# AT32F403A register map
Vendor: Keil; Series: AT32F403A; File version: 1.0
CPU: CM4 r0p1, little endian, no MPU, FPU, 4 interrupt priority bits
Registers are 32-bit, read-write, reset 0x0 unless marked. A register's access mark holds for its fields unless they carry their own. Offsets are from the block's base; [hi:lo] are bit positions; {n}, {i} and the like mark numbered series; 'fields as' and 'values as' point back to an identical list.

## CRM — Clock and reset management
Base 0x40021000
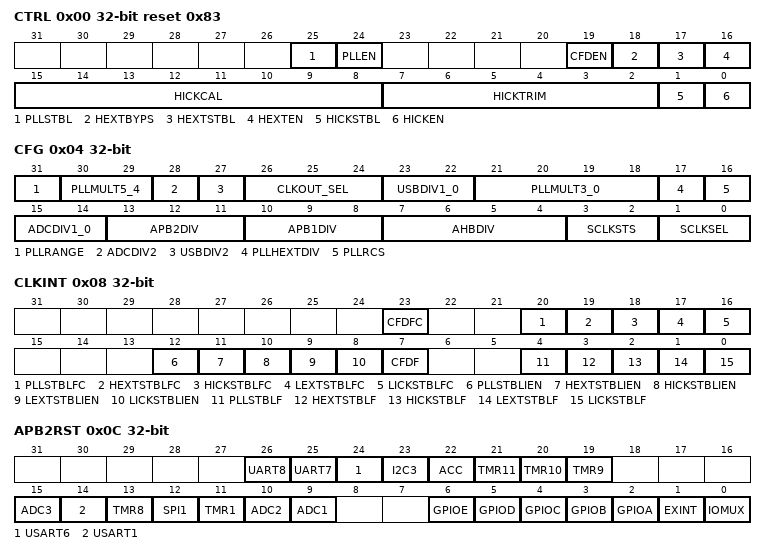
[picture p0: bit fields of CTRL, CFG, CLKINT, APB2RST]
0x00 CTRL reset 0x83 — Clock control register
  [25] PLLSTBL ro — PLL clock ready flag
    0=NotReady; 1=Ready
  [24] PLLEN — PLL enable
    on read: 0=Disabled (PLL is disabled); 1=Enabled (PLL is enabled) | on write: 0=Disable (PLL disable); 1=Enable (PLL enable)
  [19] CFDEN — Clock failure detection enable
    on read: 0=Disabled (Clock failure detector is disabled); 1=Enabled (Clock failure detector is enabled) | on write: 0=Disable (Clock failure detector disable); 1=Enable (Clock failure detector enable)
  [18] HEXTBYPS — High speed exernal crystal bypass
    on read: 0=Disabled (High speed external crystal bypass is disabled); 1=Enabled (High speed external crystal bypass is enabled) | on write: 0=Disable (High speed external crystal bypass disable); 1=Enable (High speed external crystal bypass enable)
  [17] HEXTSTBL ro — High speed exernal crystal ready flag
    0=NotReady; 1=Ready
  [16] HEXTEN — High speed exernal crystal enable
    on read: 0=Disabled (High speed external crystal is disabled); 1=Enabled (High speed external crystal is enabled) | on write: 0=Disable (High speed external crystal disable); 1=Enable (High speed external crystal enable)
  [15:8] HICKCAL ro — High speed internal clock calibration
  [7:2] HICKTRIM — High speed internal clock trimming
  [1] HICKSTBL ro — High speed internal clock ready flag
    0=NotReady; 1=Ready
  [0] HICKEN — High speed internal clock enable
    on read: 0=Disabled (High speed internal clock is disabled); 1=Enabled (High speed internal clock is enabled) | on write: 0=Disable (High speed internal clock disable); 1=Enable (High speed internal clock enable)
0x04 CFG — Clock configuration register (CRM_CFG)
  [31] PLLRANGE — PLL clock output frequency up 72MHz or not
  [30:29] PLLMULT5_4 — PLL Multiplication Factor bit5 and bit4
  [28] ADCDIV2 — ADC division bit2
  [27] USBDIV2 — USB division bit2
  [26:24] CLKOUT_SEL — Clock output selection bit2 to bit0
  [23:22] USBDIV1_0 — USB division bit1 and bit0
  [21:18] PLLMULT3_0 — PLL Multiplication Factor bit3 to bit0
  [17] PLLHEXTDIV — HEXT division selection for PLL entry clock
    0=HEXT; 1=Div2 (HEXT/2)
  [16] PLLRCS — PLL reference clock select
  [15:14] ADCDIV1_0 — ADC division bit1 and bit0
  [13:11] APB2DIV — APB2 division
    4=Div2 (HCLK divided by 2); 5=Div4 (HCLK divided by 4); 6=Div8 (HCLK divided by 8); 7=Div16 (HCLK divided by 16); other=HCLK (The divided HCLK is used as APB clock)
  [10:8] APB1DIV — APB1 division
    values as APB2DIV
  [7:4] AHBDIV — AHB division
    8=Div2 (SCLK divided by 2); 9=Div4 (SCLK divided by 4); 10=Div8 (SCLK divided by 8); 11=Div16 (SCLK divided by 16); 12=Div64 (SCLK divided by 64); 13=Div128 (SCLK divided by 128); 14=Div256 (SCLK divided by 256); 15=Div512 (SCLK divided by 512); other=SCLK (The SCLK is used as AHB clock)
  [3:2] SCLKSTS ro — System Clock select Status
    0=HICK (System clock from HICK); 1=HEXT (System clock from HEXT); 2=PLL (System clock from PLL)
  [1:0] SCLKSEL — System clock select
    values as SCLKSTS
0x08 CLKINT — Clock interrupt register (CRM_CLKINT)
  [23] CFDFC wo — Clock failure detection interrupt clear
  [20] PLLSTBLFC wo — PLL ready interrupt clear
  [19] HEXTSTBLFC wo — HEXT ready interrupt clear
  [18] HICKSTBLFC wo — HICK ready interrupt clear
  [17] LEXTSTBLFC wo — LEXT ready interrupt clear
  [16] LICKSTBLFC wo — LICK ready interrupt clear
  [12] PLLSTBLIEN — PLL ready interrupt enable
  [11] HEXTSTBLIEN — HEXT ready interrupt enable
  [10] HICKSTBLIEN — HICK ready interrupt enable
  [9] LEXTSTBLIEN — LEXT ready interrupt enable
  [8] LICKSTBLIEN — LICK ready interrupt enable
  [7] CFDF ro — Clock failure detection interrupt flag
  [4] PLLSTBLF ro — PLL ready interrupt flag
  [3] HEXTSTBLF ro — HEXT ready interrupt flag
  [2] HICKSTBLF ro — HICK ready interrupt flag
  [1] LEXTSTBLF ro — LEXT ready interrupt flag
  [0] LICKSTBLF ro — LICK ready interrupt flag
0x0C APB2RST — APB2 peripheral reset register (CRM_APB2RST)
  [26] UART8 — UART8 reset
  [25] UART7 — UART7 reset
  [24] USART6 — USART6 reset
  [23] I2C3 — I2C3 reset
  [22] ACC — ACC reset
  [21] TMR11 — Timer11 reset
  [20] TMR10 — Timer10 reset
  [19] TMR9 — Timer9 reset
  [15] ADC3 — ADC3 reset
  [14] USART1 — USART1 reset
  [13] TMR8 — Timer8 reset
  [12] SPI1 — SPI1 reset
  [11] TMR1 — Timer1 reset
  [10] ADC2 — ADC2 reset
  [9] ADC1 — ADC1 reset
  [6] GPIOE — IO port E reset
  [5] GPIOD — IO port D reset
  [4] GPIOC — IO port C reset
  [3] GPIOB — IO port B reset
  [2] GPIOA — IO port A reset
  [1] EXINT — External interrupt reset
  [0] IOMUX — MUX function I/O reset
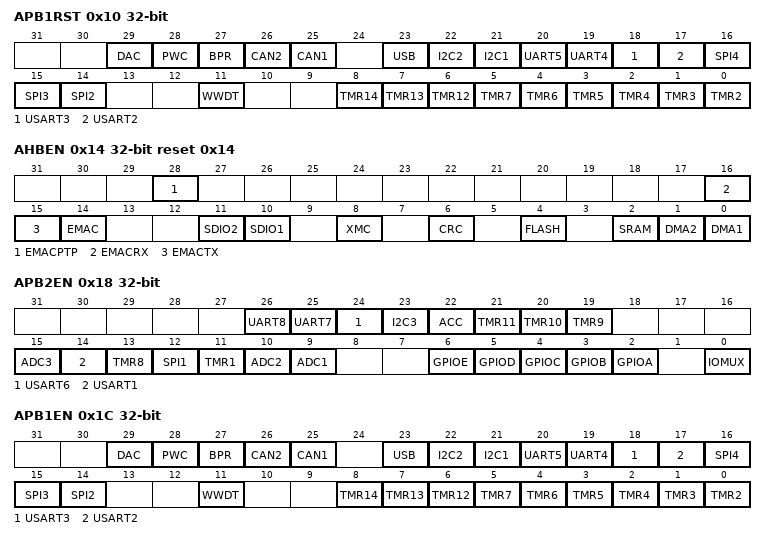
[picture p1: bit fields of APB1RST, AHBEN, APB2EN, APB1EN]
0x10 APB1RST — APB1 peripheral reset register (CRM_APB1RST)
  [29] DAC — DAC reset
  [28] PWC — Power controller reset
  [27] BPR — Battery powered domain register reset
  [26] CAN2 — CAN2 reset
  [25] CAN1 — CAN1 reset
  [23] USB — USB reset
  [22] I2C2 — I2C2 reset
  [21] I2C1 — I2C1 reset
  [20] UART5 — UART 5 reset
  [19] UART4 — UART 4 reset
  [18] USART3 — USART 3 reset
  [17] USART2 — USART 2 reset
  [16] SPI4 — SPI4 reset
  [15] SPI3 — SPI3 reset
  [14] SPI2 — SPI2 reset
  [11] WWDT — Window watchdog timer reset
  [8] TMR14 — Timer 14 reset
  [7] TMR13 — Timer 13 reset
  [6] TMR12 — Timer 12 reset
  [n-2] TMR{n} (n=2..7) — Timer {n} reset
0x14 AHBEN reset 0x14 — AHB Peripheral Clock enable register (CRM_AHBEN)
  [28] EMACPTP — EMACPTP clock enable
  [16] EMACRX — EMACEN Rx clock enable
  [15] EMACTX — EMACEN Tx clock enable
  [14] EMAC — EMACEN clock enable
  [11] SDIO2 — SDIO2 clock enable
  [10] SDIO1 — SDIO1 clock enable
  [8] XMC — XMC clock enable
  [6] CRC — CRC clock enable
  [4] FLASH — FLASH clock enable
  [2] SRAM — SRAM interface clock enable
  [1] DMA2 — DMA2 clock enable
  [0] DMA1 — DMA1 clock enable
0x18 APB2EN — APB2 peripheral clock enable register (CRM_APB2EN)
  [26] UART8 — UART8 clock enable
  [25] UART7 — UART7 clock enable
  [24] USART6 — USART6 clock enable
  [23] I2C3 — I2C3 clock enable
  [22] ACC — ACC clock enable
  [21] TMR11 — Timer11 clock enable
  [20] TMR10 — Timer10 clock enable
  [19] TMR9 — Timer9 clock enable
  [15] ADC3 — ADC3 clock enable
  [14] USART1 — USART1 clock enable
  [13] TMR8 — Timer8 clock enable
  [12] SPI1 — SPI1 clock enable
  [11] TMR1 — Timer1 clock enable
  [10] ADC2 — ADC2 clock enable
  [9] ADC1 — ADC1 clock enable
  [6] GPIOE — I/O port E clock enable
  [5] GPIOD — I/O port D clock enable
  [4] GPIOC — I/O port C clock enable
  [3] GPIOB — I/O port B clock enable
  [2] GPIOA — I/O port A clock enable
  [0] IOMUX — MUX function I/O clock enable
0x1C APB1EN — APB1 peripheral clock enable register (CRM_APB1EN)
  [29] DAC — DAC clock enable
  [28] PWC — Power clock enable
  [27] BPR — Barrery powered domain register clock enable
  [26] CAN2 — CAN2 clock enable
  [25] CAN1 — CAN1 clock enable
  [23] USB — USB clock enable
  [22] I2C2 — I2C2 clock enable
  [21] I2C1 — I2C1 clock enable
  [20] UART5 — UART5 clock enable
  [19] UART4 — UART4 clock enable
  [18] USART3 — USART3 clock enable
  [17] USART2 — USART2 clock enable
  [16] SPI4 — SPI4 clock enable
  [15] SPI3 — SPI3 clock enable
  [14] SPI2 — SPI2 clock enable
  [11] WWDT — Window watchdog timer clock enable
  [8] TMR14 — Timer14 clock enable
  [7] TMR13 — Timer13 clock enable
  [6] TMR12 — Timer12 clock enable
  [n-2] TMR{n} (n=2..7) — Timer{n} clock enable
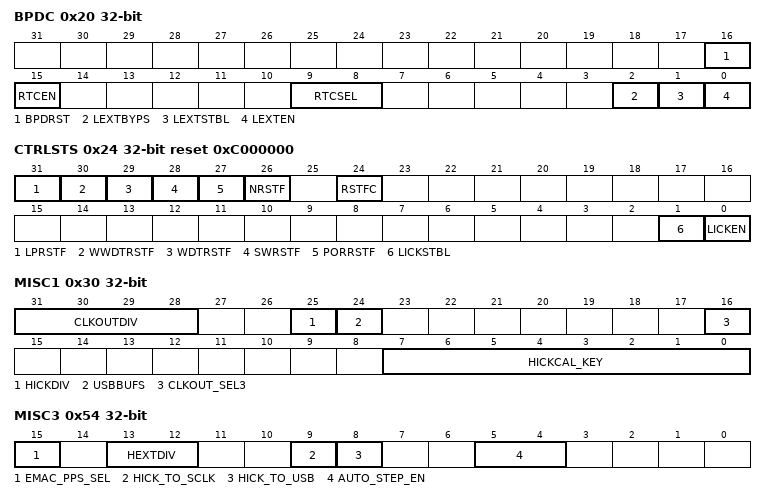
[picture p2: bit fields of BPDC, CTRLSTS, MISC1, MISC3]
0x20 BPDC — Battery powered domain control register (CRM_BPDC)
  [16] BPDRST — Battery powered domain software reset
  [15] RTCEN — RTC clock enable
  [9:8] RTCSEL — RTC clock selection
  [2] LEXTBYPS — Low speed external crystal bypass
  [1] LEXTSTBL ro — Low speed external crystal ready
  [0] LEXTEN — Low speed external crystal enable
0x24 CTRLSTS reset 0xC000000 — Control/status register (CRM_CTRLSTS)
  [31] LPRSTF — Low-power reset flag
  [30] WWDTRSTF — Window watchdog timer reset flag
  [29] WDTRSTF — Watchdog timer reset flag
  [28] SWRSTF — Software reset flag
  [27] PORRSTF — POR/LVR reset flag
  [26] NRSTF — PIN reset flag
  [24] RSTFC — Reset flag clear
  [1] LICKSTBL ro — Low speed internal clock ready
  [0] LICKEN — Low speed internal clock enable
0x28 AHBRST — AHB reset register
  [14] EMAC — EMAC reset
0x30 MISC1 — Miscellaneous register1
  [31:28] CLKOUTDIV — Clock output division
  [25] HICKDIV — HICK 6 divider selection
  [24] USBBUFS — USB buffer size selection
  [16] CLKOUT_SEL3 — Clock output bit3
  [7:0] HICKCAL_KEY — HICKCAL write key value
0x50 MISC2 — Miscellaneous register2
  [16] CLK_TO_TMR — Clock output internal connect to timer10
0x54 MISC3 — Miscellaneous register3
  [15] EMAC_PPS_SEL — Ethernet pulse width Select
  [13:12] HEXTDIV — HEXT division
  [9] HICK_TO_SCLK — HICK to system clock
  [8] HICK_TO_USB — HICK to usb clock
  [5:4] AUTO_STEP_EN
0x5C INTMAP — Interrupt remap register
  [0] USB_INT_MAP — USBDEV interrupt remap
